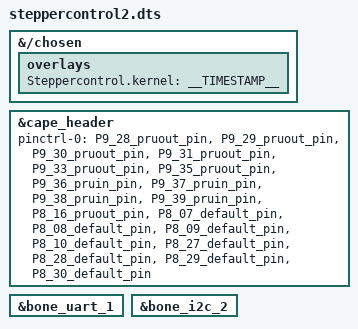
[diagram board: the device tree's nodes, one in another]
// SPDX-License-Identifier: GPL-2.0

/* This Overlay opens up PRG0-PRU0 Pins for use 7 outputs (accesed through /sys/class/remoteproc/remoteproc0/



/*
 * Copyright (C) 2022 Jason Kridner, BeagleBoard.org Foundation
 */

/dts-v1/;
/plugin/;

#include <dt-bindings/gpio/gpio.h>
#include <dt-bindings/interrupt-controller/arm-gic.h>
#include <dt-bindings/interrupt-controller/irq.h>
#include <dt-bindings/pinctrl/k3.h>
#include <dt-bindings/board/k3-j721e-bone-pins.h>
#include <dt-bindings/soc/ti,sci_pm_domain.h>
#include <dt-bindings/input/linux-event-codes.h>

/*
 * Helper to show loaded overlays under: /proc/device-tree/chosen/overlays/
 */


&{/chosen} {
	overlays {
		Steppercontrol.kernel = __TIMESTAMP__;
	};
};
&cape_header {
	pinctrl-names = "default";
	pinctrl-0 = <
		&P9_28_pruout_pin	
		&P9_29_pruout_pin   
		&P9_30_pruout_pin   
		&P9_31_pruout_pin  
		&P9_33_pruout_pin   
		&P9_35_pruout_pin   
		&P9_36_pruin_pin	
		&P9_37_pruin_pin   
		&P9_38_pruin_pin
		&P9_39_pruin_pin
		&P8_16_pruout_pin   
		&P8_07_default_pin
		&P8_08_default_pin
		&P8_09_default_pin
		&P8_10_default_pin
		&P8_27_default_pin
		&P8_28_default_pin
		&P8_29_default_pin
		&P8_30_default_pin
		
		
		
				
	>;
};

&bone_uart_1 {
	/* tested with sudo agetty 115200 ttyS4 */
	status = "okay";
};

&bone_i2c_2 {
	status = "okay";
};







